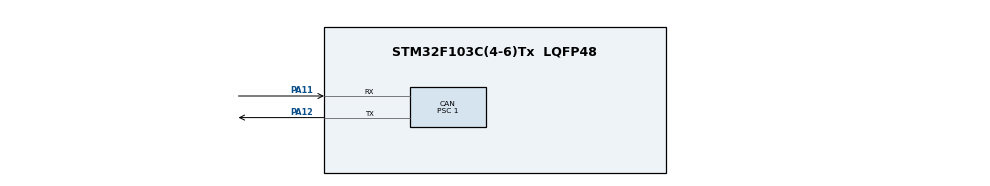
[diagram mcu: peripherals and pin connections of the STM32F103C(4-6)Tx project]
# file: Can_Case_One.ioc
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CAN.BS1=CAN_BS1_6TQ
CAN.CalculateBaudRate=1000000
CAN.CalculateTimeBit=1000
CAN.CalculateTimeQuantum=125.0
CAN.Mode=CAN_MODE_LOOPBACK
CAN.Prescaler=1
Mcu.Family=STM32F1
Mcu.Name=STM32F103C(4-6)Tx
Mcu.Package=LQFP48
NVIC.PriorityGroup=NVIC_PRIORITYGROUP_4
PA11.Mode=CAN_Activate
PA11.Signal=CAN_RX
PA12.Mode=CAN_Activate
PA12.Signal=CAN_TX
PA13.Mode=Serial_Wire
PA13.Signal=SYS_JTMS-SWDIO
PA14.Mode=Serial_Wire
PA14.Signal=SYS_JTCK-SWCLK
ProjectManager.HeapSize=0x200
ProjectManager.StackSize=0x400
ProjectManager.TargetToolchain=STM32CubeIDE
RCC.APB1Freq_Value=8000000
RCC.APB2Freq_Value=8000000
board=custom

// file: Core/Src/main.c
/* USER CODE BEGIN Header */
/**
 ******************************************************************************
 * @file           : main.c
 * @brief          : Main program body
 ******************************************************************************
 * @attention
 *
 * Copyright (c) 2024 STMicroelectronics.
 * All rights reserved.
 *
 * This software is licensed under terms that can be found in the LICENSE file
 * in the root directory of this software component.
 * If no LICENSE file comes with this software, it is provided AS-IS.
 *
 ******************************************************************************
 */
/* USER CODE END Header */
#include "main.h"

CAN_HandleTypeDef hcan;

void SystemClock_Config(void);
static void MX_GPIO_Init(void);
static void MX_CAN_Init(void);

void CAN_TX(uint32_t ID, uint8_t DLC, uint8_t *payload)
    {
    uint8_t no_Free_Boxes = 0, mailbox_written;
    /*
     *
     *** Polling mode operation ***
     ==============================
     [..]
     (#) Reception:
     (++) Monitor reception of message using HAL_CAN_GetRxFifoFillLevel()
     until at least one message is received.
     (++) Then get the message using HAL_CAN_GetRxMessage().

     (#) Transmission:
     (++) Monitor the Tx mailboxes availability until at least one Tx
     mailbox is free, using HAL_CAN_GetTxMailboxesFreeLevel().
     (++) Then request transmission of a message using
     HAL_CAN_AddTxMessage().
     */
    no_Free_Boxes = HAL_CAN_GetTxMailboxesFreeLevel(&hcan);
    CAN_TxHeaderTypeDef Header;
    Header.DLC = DLC;
    Header.IDE = CAN_ID_STD;
    Header.RTR = CAN_RTR_DATA;
    Header.StdId = ID;
    if (no_Free_Boxes)
	{
	if (HAL_CAN_AddTxMessage(&hcan, &Header, payload, &mailbox_written)
		!= HAL_OK)
	    {
	    Error_Handler();
	    }
	}
    while (HAL_CAN_IsTxMessagePending(&hcan, mailbox_written))
	;

    }

int main(void)
    {

    /* MCU Configuration--------------------------------------------------------*/

    /* Reset of all peripherals, Initializes the Flash interface and the Systick. */
    HAL_Init();

    /* Configure the system clock */
    SystemClock_Config();

    /* Initialize all configured peripherals */
    MX_GPIO_Init();
    MX_CAN_Init();
    /* USER CODE BEGIN 2 */
    if (HAL_CAN_Start(&hcan) != HAL_OK)
	Error_Handler();

    /* USER CODE END 2 */
    uint8_t Tx_Data[] = "CAN Num ";
    /* Infinite loop */
    /* USER CODE BEGIN WHILE */
    uint8_t Framno = 0;
    while (1)
	{
	Tx_Data[7] = Framno++;
	CAN_TX(0x3FF, 8, Tx_Data);
	/* USER CODE END WHILE */

	}
    }

void SystemClock_Config(void)
    {
    RCC_OscInitTypeDef RCC_OscInitStruct =
	{
	0
	};
    RCC_ClkInitTypeDef RCC_ClkInitStruct =
	{
	0
	};

    /** Initializes the RCC Oscillators according to the specified parameters
     * in the RCC_OscInitTypeDef structure.
     */
    RCC_OscInitStruct.OscillatorType = RCC_OSCILLATORTYPE_HSI;
    RCC_OscInitStruct.HSIState = RCC_HSI_ON;
    RCC_OscInitStruct.HSICalibrationValue = RCC_HSICALIBRATION_DEFAULT;
    RCC_OscInitStruct.PLL.PLLState = RCC_PLL_NONE;
    if (HAL_RCC_OscConfig(&RCC_OscInitStruct) != HAL_OK)
	{
	Error_Handler();
	}

    /** Initializes the CPU, AHB and APB buses clocks
     */
    RCC_ClkInitStruct.ClockType = RCC_CLOCKTYPE_HCLK | RCC_CLOCKTYPE_SYSCLK
	    | RCC_CLOCKTYPE_PCLK1 | RCC_CLOCKTYPE_PCLK2;
    RCC_ClkInitStruct.SYSCLKSource = RCC_SYSCLKSOURCE_HSI;
    RCC_ClkInitStruct.AHBCLKDivider = RCC_SYSCLK_DIV1;
    RCC_ClkInitStruct.APB1CLKDivider = RCC_HCLK_DIV1;
    RCC_ClkInitStruct.APB2CLKDivider = RCC_HCLK_DIV1;

    if (HAL_RCC_ClockConfig(&RCC_ClkInitStruct, FLASH_LATENCY_0) != HAL_OK)
	{
	Error_Handler();
	}
    }

static void MX_CAN_Init(void)
    {

    hcan.Instance = CAN1;
    hcan.Init.Prescaler = 1;
    hcan.Init.Mode = CAN_MODE_LOOPBACK;
    hcan.Init.SyncJumpWidth = CAN_SJW_1TQ;
    hcan.Init.TimeSeg1 = CAN_BS1_6TQ;
    hcan.Init.TimeSeg2 = CAN_BS2_1TQ;
    hcan.Init.TimeTriggeredMode = DISABLE;
    hcan.Init.AutoBusOff = DISABLE;
    hcan.Init.AutoWakeUp = DISABLE;
    hcan.Init.AutoRetransmission = DISABLE;
    hcan.Init.ReceiveFifoLocked = DISABLE;
    hcan.Init.TransmitFifoPriority = DISABLE;
    if (HAL_CAN_Init(&hcan) != HAL_OK)
	{
	Error_Handler();
	}

    }

static void MX_GPIO_Init(void)
    {

    /* GPIO Ports Clock Enable */
    __HAL_RCC_GPIOA_CLK_ENABLE();

    }

void Error_Handler(void)
    {
    __disable_irq();
    while (1)
	{
	}
    }
